# PIC32MZ0512EFF144 device description
Architecture: 32xxxx; Family: PIC32MZEF; Series: PIC32MZ
Registers are 32-bit, read-write, no defined reset value unless marked. A register's access mark holds for its fields unless they carry their own. Offsets are from the block's base; [hi:lo] are bit positions; 'fields as' and 'values as' point back to an identical list.

## ETH
Instances: ETH 0x1f882000 in periph_pb5_std
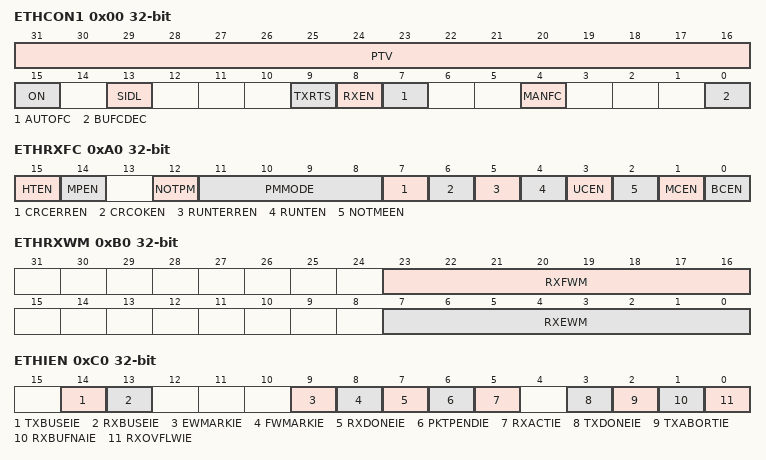
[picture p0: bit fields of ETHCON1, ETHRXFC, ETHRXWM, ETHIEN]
0x00 ETHCON1 — Ethernet Controller Control Register 1
  [31:16] PTV
  [15] ON — Ethernet ON bit
    1=Ethernet module is enabled; 0=Ethernet module is disabled
  [13] SIDL — Ethernet Stop in Idle Mode bit
    1=Ethernet module transfers are paused during Idle mode; 0=Ethernet module transfers continue during Idle mode
  [9] TXRTS — Transmit Request to Send bit
    1=Activate the TX logic and send the packet(s) defined in the TX EDT; 0=Stop transmit (when cleared by software) or transmit done (when cleared by hardware)
  [8] RXEN — Receive Enable bit
    1=Enable RX logic; 0=Disable RX logic
  [7] AUTOFC — Automatic Flow Control bit
    1=Automatic Flow Control enabled; 0=Automatic Flow Control disabled
  [4] MANFC — Manual Flow Control bit
    1=Manual Flow Control is enabled; 0=Manual Flow Control is disabled
  [0] BUFCDEC
0x10 ETHCON2 — Ethernet Controller Control Register 2
  [10:4] RXBUFSZ — RX Data Buffer Size for All RX Descriptors bits
    127=RX data Buffer size for descriptors is 2032 bytes; 96=RX data Buffer size for descriptors is 1536 bytes; 3=RX data Buffer size for descriptors is 48 bytes; 2=RX data Buffer size for descriptors is 32 bytes; 1=RX data Buffer size for descriptors is 16 bytes
0x20 ETHTXST — Ethernet Controller TX Packet Descriptor Start Address Register
  [31:2] TXSTADDR
0x30 ETHRXST — Ethernet Controller RX Packet Descriptor Start Address Register
  [31:2] RXSTADDR
0x40 ETHHT0 — Ethernet Controller Hash Table 0 Register
  [31:0] HT
0x50 ETHHT1 — Ethernet Controller Hash Table 1 Register
  [31:0] HT
0x60 ETHPMM0 — Ethernet Controller Pattern Match Mask 0 Register
  [31:0] PMM
0x70 ETHPMM1 — Ethernet Controller Pattern Match Mask 1 Register
  [31:0] PMM
0x80 ETHPMCS — Ethernet Controller Pattern Match Checksum Register
  [15:0] PMCS
0x90 ETHPMO — Ethernet Controller Pattern Match Offset Register
  [15:0] PMO
0xA0 ETHRXFC — Ethernet Controller Receive Filter Configuration Register
  [15] HTEN — Enable Hash Table Filtering bit
    1=Enable Hash Table Filtering; 0=Disable Hash Table Filtering
  [14] MPEN — Magic Packet Enable bit
    1=Enable Magic Packet Filtering; 0=Disable Magic Packet Filtering
  [12] NOTPM — Pattern Match Inversion bit
    1=The Pattern Match Checksum must not match for a successful Pattern Match to occur; 0=The Pattern Match Checksum must match for a successful Pattern Match to occur
  [11:8] PMMODE — Pattern Match Mode bits
    9=Pattern match is successful if (NOTPM = 1 XOR Pattern Match Checksum matches) AND (Packet = Magic Packet)(1; 8=Pattern match is successful if (NOTPM = 1 XOR Pattern Match Checksum matches) AND (Hash Table Filter match)(1; 7=Pattern match is successful if (NOTPM = 1 XOR Pattern Match Checksum matches) AND(Destination Address = Broadcast Address)(1); 6=Pattern match is successful if (NOTPM = 1 XOR Pattern Match Checksum matches) AND (Destination Address = Broadcast Address)(1); 5=Pattern match is successful if (NOTPM = 1 XOR Pattern Match Checksum matches) AND (Destination Address = Unicast Address)(1); 4=Pattern match is successful if (NOTPM = 1 XOR Pattern Match Checksum matches) AND (Destination Address = Unicast Address)(1); 3=Pattern match is successful if (NOTPM = 1 XOR Pattern Match Checksum matches) AND (Destination Address = Station Address)(1); 2=Pattern match is successful if (NOTPM = 1 XOR Pattern Match Checksum matches) AND(Destination Address = Station Address)(1); 1=Pattern match is successful if (NOTPM = 1 XOR Pattern Match Checksum matches)(1); 0=Pattern Match is disabled; pattern match is always unsuccessful
  [7] CRCERREN — CRC Error Collection Enable bit
    1=The received packet CRC must be invalid for the packet to be accepted; 0=Disable CRC Error Collection filtering
  [6] CRCOKEN — CRC OK Enable bit
    1=The received packet CRC must be valid for the packet to be accepted; 0=Disable CRC filtering
  [5] RUNTERREN — Runt Error Collection Enable bit
    1=The received packet must be a runt packet for the packet to be accepted; 0=Disable Runt Error Collection filtering
  [4] RUNTEN — Runt Enable bit
    1=The received packet must not be a runt packet for the packet to be accepted; 0=Disable Runt filtering
  [3] UCEN — Unicast Enable bit
    1=Enable Unicast Filtering; 0=Disable Unicast Filtering
  [2] NOTMEEN — Not Me Unicast Enable bit
    1=Enable Not Me Unicast Filtering; 0=Disable Not Me Unicast Filtering
  [1] MCEN — Multicast Enable bit
    1=Enable Multicast Filtering; 0=Disable Multicast Filtering
  [0] BCEN — Broadcast Enable bit
    1=Enable Broadcast Filtering; 0=Disable Broadcast Filtering
0xB0 ETHRXWM — Ethernet Controller Receive Watermarks Register
  [23:16] RXFWM, [7:0] RXEWM
0xC0 ETHIEN — Ethernet Controller Interrupt Enable Register
  [14] TXBUSEIE — Transmit BVCI Bus Error Interrupt Enable bit
    1=Enable TXBUS Error Interrupt; 0=Disable TXBUS Error Interrupt
  [13] RXBUSEIE — Receive BVCI Bus Error Interrupt Enable bit
    1=Enable RXBUS Error Interrupt; 0=Disable RXBUS Error Interrupt
  [9] EWMARKIE — Empty Watermark Interrupt Enable bit
    1=Enable EWMARK Interrupt; 0=Disable EWMARK Interrupt
  [8] FWMARKIE — Full Watermark Interrupt Enable bit
    1=Enable FWMARK Interrupt; 0=Disable FWMARK Interrupt
  [7] RXDONEIE — Receiver Done Interrupt Enable bit
    1=Enable RXDONE Interrupt; 0=Disable RXDONE Interrupt
  [6] PKTPENDIE — Packet Pending Interrupt Enable bit
    1=Enable PKTPEND Interrupt; 0=Disable PKTPEND Interrupt
  [5] RXACTIE — RX Activity Interrupt Enable bit
    1=Enable RXACT Interrupt; 0=Disable RXACT Interrupt
  [3] TXDONEIE — Transmitter Done Interrupt Enable bit
    1=Enable TXDONE Interrupt; 0=Disable TXDONE Interrupt
  [2] TXABORTIE — Transmitter Abort Interrupt Enable bit
    1=Enable TXABORT Interrupt; 0=Disable TXABORT Interrupt
  [1] RXBUFNAIE — Receive Buffer Not Available Interrupt Enable bit
    1=Enable RXBUFNA Interrupt; 0=Disable RXBUFNA Interrupt
  [0] RXOVFLWIE — Receive FIFO Overflow Interrupt Enable bit
    1=Enable RXOVFLW Interrupt; 0=Disable RXOVFLW Interrupt
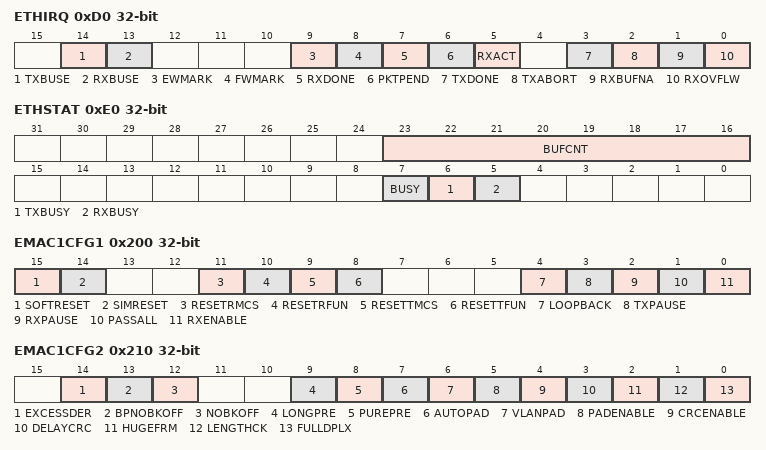
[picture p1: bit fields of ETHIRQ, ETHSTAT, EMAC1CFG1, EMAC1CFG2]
0xD0 ETHIRQ — Ethernet Controller Interrupt Request Register
  [14] TXBUSE — Transmit BVCI Bus Error Interrupt bit
    1=BVCI Bus Error has occurred; 0=BVCI Bus Error has not occurred
  [13] RXBUSE — Receive BVCI Bus Error Interrupt bit
    values as TXBUSE
  [9] EWMARK — Empty Watermark Interrupt bit
    1=Empty Watermark pointer reached; 0=No interrupt pending
  [8] FWMARK — Full Watermark Interrupt bit
    1=Full Watermark pointer reached; 0=No interrupt pending
  [7] RXDONE — Receive Done Interrupt bit
    1=RX packet was successfully received; 0=No interrupt pending
  [6] PKTPEND — Packet Pending Interrupt bit
    1=RX packet pending in memory; 0=RX packet is not pending in memory
  [5] RXACT — Receive Activity Interrupt bit
    1=RX packet data was successfully received; 0=No interrupt pending
  [3] TXDONE — Transmit Done Interrupt bit
    1=TX packet was successfully sent; 0=No interrupt pending
  [2] TXABORT — Transmit Abort Condition Interrupt bit
    1=TX abort condition occurred on the last TX packet; 0=No interrupt pending
  [1] RXBUFNA — Receive Buffer Not Available Interrupt bit
    1=RX Buffer Descriptor Not Available condition has occurred; 0=No interrupt pending
  [0] RXOVFLW — Receive FIFO Over Flow Error bit
    1=RX FIFO Overflow Error condition has occurred; 0=No interrupt pending
0xE0 ETHSTAT — Ethernet Controller Status Register
  [23:16] BUFCNT
  [7] BUSY
  [6] TXBUSY — Transmit Busy bit
    1=TX logic is receiving data; 0=TX logic is idle
  [5] RXBUSY — Receive Busy bit
    1=RX logic is receiving data; 0=RX logic is idle
0x100 ETHRXOVFLOW — Ethernet Controller Receive Overflow Statistics Register
  [15:0] RXOVFLWCNT
0x110 ETHFRMTXOK — Ethernet Controller Frames Transmitted OK Statistics Register
  [15:0] FRMTXOKCNT
0x120 ETHSCOLFRM — Ethernet Controller Single Collision Frames Statistics Register
  [15:0] SCOLFRMCNT
0x130 ETHMCOLFRM — Ethernet Controller Multiple Collision Frames Statistics Register
  [15:0] MCOLFRMCNT
0x140 ETHFRMRXOK — Ethernet Controller Frames Received OK Statistics Register
  [15:0] FRMRXOKCNT
0x150 ETHFCSERR — Ethernet Controller Frame Check Sequence Error Statistics Register
  [15:0] FCSERRCNT
0x160 ETHALGNERR — Ethernet Controller Alignment Errors Statistics Register
  [15:0] ALGNERRCNT
0x200 EMAC1CFG1 — Ethernet Controller MAC Configuration 1 Register
  [15] SOFTRESET
  [14] SIMRESET
  [11] RESETRMCS
  [10] RESETRFUN
  [9] RESETTMCS
  [8] RESETTFUN
  [4] LOOPBACK — MAC Loopback mode bit
    1=MAC Transmit interface is loop backed to the MAC Receive interface; 0=MAC normal operation
  [3] TXPAUSE — MAC TX Flow Control bit
    1=PAUSE Flow Control frames are allowed to be transmitted; 0=PAUSE Flow Control frames are blocked
  [2] RXPAUSE — MAC RX Flow Control bit
    1=The MAC acts upon received PAUSE Flow Control frames; 0=Received PAUSE Flow Control frames are ignored
  [1] PASSALL — MAC Pass all Receive Frames bit
    1=The MAC will accept all frames regardless of type (Normal vs. Control); 0=The received Control frames are ignored
  [0] RXENABLE — MAC Receive Enable bit
    1=Enable the MAC receiving of frames; 0=Disable the MAC receiving of frames
0x210 EMAC1CFG2 — Ethernet Controller MAC Configuration 2 Register
  [14] EXCESSDER — Excess Defer bit
    1=The MAC will defer to carrier indefinitely as per the Standard; 0=The MAC will abort when the excessive deferral limit is reached
  [13] BPNOBKOFF — Backpressure/No Backoff bit
    1=The MAC after incidentally causing a collision during backpressure will immediately retransmit without backoff reducing the chance of further collisions and ensuring transmit packets get sent; 0=The MAC will not remove the backoff
  [12] NOBKOFF — No Backoff bit
    1=Following a collision; 0=Following a collision
  [9] LONGPRE — Long Preamble Enforcement bit
    1=The MAC only allows receive packets which contain preamble fields less than 12 bytes in length; 0=The MAC allows any length preamble as per the Standard
  [8] PUREPRE — Pure Preamble Enforcement bit
    1=The MAC will verify the content of the preamble to ensure it contains 0x55 and is error-free. A packet with errors in its preamble is discarded; 0=The MAC does not perform any preamble checking
  [7] AUTOPAD — Automatic Detect Pad Enable bit
    1=The MAC will automatically detect the type of frame; 0=The MAC does not perform automatic detection
  [6] VLANPAD — VLAN Pad Enable bit
    1=The MAC will pad all short frames to 64 bytes and append a valid CRC; 0=The MAC does not perform padding of short frames
  [5] PADENABLE — Pad/CRC Enable bit
    1=The MAC will pad all short frames; 0=The frames presented to the MAC have a valid length
  [4] CRCENABLE — CRC Enable1 bit
    1=The MAC will append a CRC to every frame whether padding was required or not. Must be set if the PADENABLE bit is set.; 0=The frames presented to the MAC have a valid CRC
  [3] DELAYCRC — Delayed CRC bit
    1=Four bytes of header (ignored by the CRC function); 0=No proprietary header
  [2] HUGEFRM — Huge Frame enable bit
    1=Frames of any length are transmitted and received; 0=Huge frames are not allowed for receive or transmit
  [1] LENGTHCK — Frame Length checking bit
    1=Both transmit and receive frame lengths are compared to the Length/Type field. If the Length/Type field represents a length then the check is performed. Mismatches are reported on the transmit/receive statistics vector.; 0=Length/Type field check is not performed
  [0] FULLDPLX — Full-Duplex Operation bit
    1=The MAC operates in Full-Duplex mode; 0=The MAC operates in Half-Duplex mode
0x220 EMAC1IPGT — Ethernet Controller MAC Back-to-Back Interpacket Gap Register
  [6:0] B2BIPKTGP
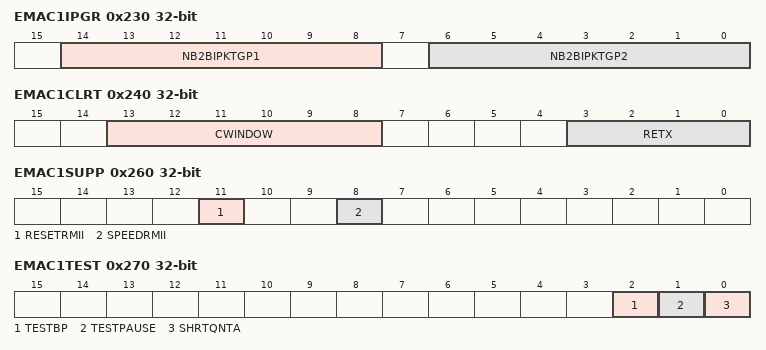
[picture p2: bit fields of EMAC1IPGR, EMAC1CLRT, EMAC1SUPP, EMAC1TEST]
0x230 EMAC1IPGR — Ethernet Controller MAC Non-Back-to-Back Interpacket Gap Register
  [14:8] NB2BIPKTGP1, [6:0] NB2BIPKTGP2
0x240 EMAC1CLRT — Ethernet Controller MAC Collision Window/Retry Limit Register
  [13:8] CWINDOW, [3:0] RETX
0x250 EMAC1MAXF — Ethernet Controller MAC Maximum Frame Length Register
  [15:0] MACMAXF
0x260 EMAC1SUPP — Ethernet Controller MAC PHY Support Register
  [11] RESETRMII — Reset RMII Logic bit
    1=Reset the MAC RMII module; 0=Normal operation
  [8] SPEEDRMII — RMII Speed bit
    1=RMII is running at 100 Mbps; 0=RMII is running at 10 Mbps
0x270 EMAC1TEST — Ethernet Controller MAC Test Register
  [2] TESTBP — Test Backpressure bit
    1=The MAC will assert backpressure on the link. Backpressure causes preamble to be transmitted; 0=Normal operation
  [1] TESTPAUSE — Test PAUSE bit
    1=The MAC Control sub-layer will inhibit transmissions; 0=Normal operation
  [0] SHRTQNTA — Shortcut PAUSE Quanta bit
    1=The MAC reduces the effective PAUSE Quanta from 64 byte-times to 1 byte-time; 0=Normal operation
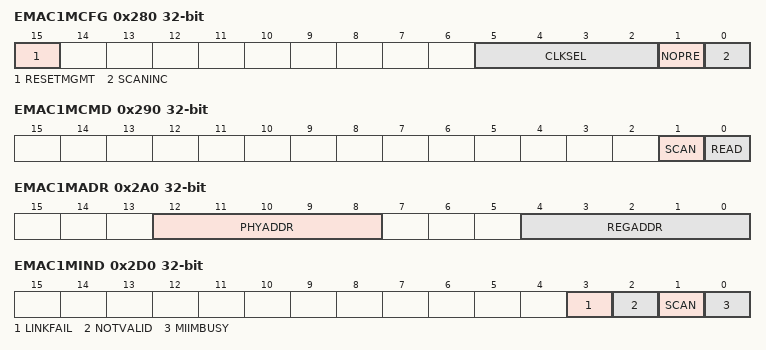
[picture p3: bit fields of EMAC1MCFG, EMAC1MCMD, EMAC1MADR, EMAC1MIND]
0x280 EMAC1MCFG — Ethernet Controller MAC MII Management Configuration Register
  [15] RESETMGMT — Test Reset MII Management bit
    1=Reset the MII Management module; 0=Normal Operation
  [5:2] CLKSEL
  [1] NOPRE — Suppress Preamble bit
    1=The MII Management will perform read/write cycles without the 32-bit preamble field. Some PHYs support suppressed preamble; 0=Normal read/write cycles are performed
  [0] SCANINC — Scan Increment bit
    1=The MII Management module will perform read cycles across a range of PHYs. The read cycles will start from address 1 through the value set in EMAC1MADR; 0=Continuous reads of the same PHY
0x290 EMAC1MCMD — Ethernet Controller MAC MII Management Command Register
  [1] SCAN — MII Management Scan Mode bit
    1=The MII Management module will perform read cycles continuously (for example; 0=Normal Operation
  [0] READ — MII Management Read Command bit
    1=The MII Management module will perform a single read cycle. The read data is returned in the EMAC1MRDD register; 0=The MII Management module will perform a write cycle. The write data is taken from the EMAC1MWTD register
0x2A0 EMAC1MADR — Ethernet Controller MAC MII Management Address Register
  [12:8] PHYADDR, [4:0] REGADDR
0x2B0 EMAC1MWTD — Ethernet Controller MAC MII Management Write Data Register
  [15:0] MWTD
0x2C0 EMAC1MRDD — Ethernet Controller MAC MII Management Read Data Register
  [15:0] MRDD
0x2D0 EMAC1MIND — Ethernet Controller MAC MII Management Indicators Register
  [3] LINKFAIL, [2] NOTVALID, [1] SCAN, [0] MIIMBUSY
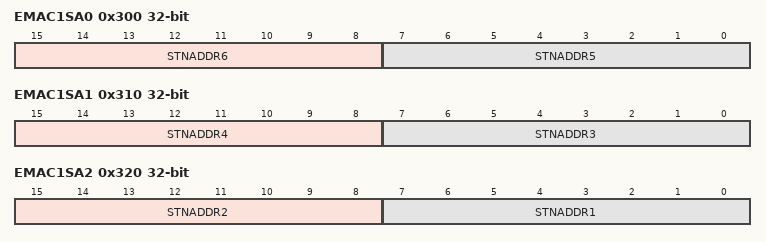
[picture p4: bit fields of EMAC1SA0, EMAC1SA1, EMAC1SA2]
0x300 EMAC1SA0 — Ethernet Controller MAC Station Address 0 Register
  [15:8] STNADDR6, [7:0] STNADDR5
0x310 EMAC1SA1 — Ethernet Controller MAC Station Address 1 Register
  [15:8] STNADDR4, [7:0] STNADDR3
0x320 EMAC1SA2 — Ethernet Controller MAC Station Address 2 Register
  [15:8] STNADDR2, [7:0] STNADDR1
Value list ETHSTAT__ETHBUSY: 128=Ethernet logic has been turned on (ON (ETHCON1) = 1) or is completing a transaction; 0=Ethernet logic is idle
